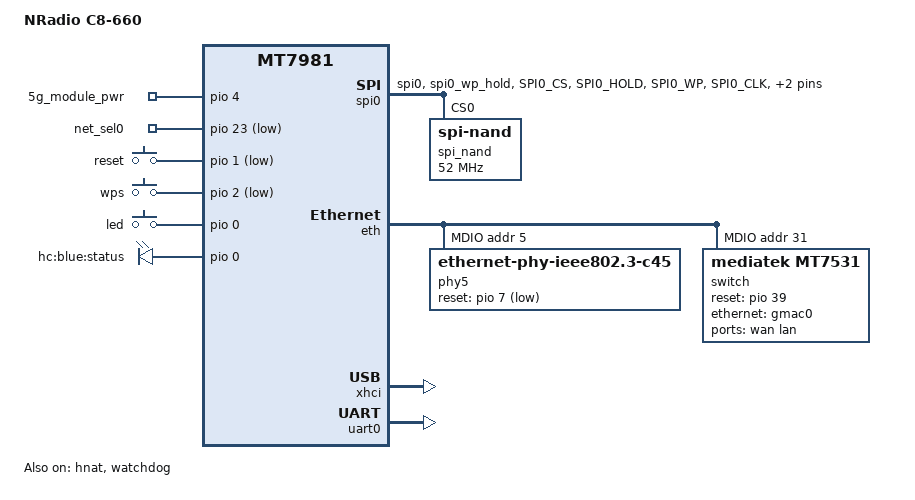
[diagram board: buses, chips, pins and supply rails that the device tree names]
//CopyRight NRadio Update By Zy143L

/dts-v1/;
#include "mt7981.dtsi"

/ {
	model = "NRadio C8-660";
	compatible = "nradio,wt9103", "mediatek,mt7981";
	
    aliases {
        led-boot = &status_blue;
        led-failsafe = &status_blue;
        led-running = &status_blue;
        led-upgrade = &status_blue;
    };

    chosen {
        bootargs = "console=ttyS0,115200n1 loglevel=8  \
                earlycon=uart8250,mmio32,0x11002000";
    };

    gpio-export {
        compatible = "gpio-export";

        cpepower {
            gpio-export,name = "5g_module_pwr";
            gpio-export,output = <1>;
            gpios = <&pio 4 GPIO_ACTIVE_HIGH>;
        };

        cpesel0 {
            gpio-export,name = "net_sel0";
            gpio-export,output = <0>;
            gpios = <&pio 23 GPIO_ACTIVE_LOW>;
        };
    };

    gpio-keys {
        compatible = "gpio-keys";

        button-reset {
            label = "reset";
            linux,code = <KEY_RESTART>;
            gpios = <&pio 1 GPIO_ACTIVE_LOW>;
        };

        button-wps {
            label = "wps";
            linux,code = <KEY_WPS_BUTTON>;
            gpios = <&pio 2 GPIO_ACTIVE_LOW>;
        };

        button-led {
            label = "led";
            linux,code = <KEY_POWER>;
            gpios = <&pio 0 GPIO_ACTIVE_HIGH>;
        };
    };

    gpio-leds {
        compatible = "gpio-leds";

        status_blue: status {
            label = "hc:blue:status";
            gpios = <&pio 0 GPIO_ACTIVE_HIGH>;
        };
    };


    nmbm_spim_nand {
        compatible = "generic,nmbm";

        #address-cells = <1>;
        #size-cells = <1>;

        lower-mtd-device = <&spi_nand>;
        forced-create;

        partitions {
            compatible = "fixed-partitions";
            #address-cells = <1>;
            #size-cells = <1>;

            partition@0 {
                label = "BL2";
                reg = <0x00000 0x0100000>;
                read-only;
            };

            partition@100000 {
                label = "u-boot-env";
                reg = <0x0100000 0x0080000>;
            };

            partition@180000 {
                label = "factory";
                reg = <0x180000 0x0180000>;
            };

            partition@300000 {
                label = "bdinfo";
                reg = <0x300000 0x0080000>;
            };

            partition@380000 {
                label = "FIP";
                reg = <0x380000 0x0200000>;
            };

            partition@580000 {
                label = "ubi";
                reg = <0x580000 0x7000000>;
            };
        };
    };
};


&spi0 {
    pinctrl-names = "default";
    pinctrl-0 = <&spi0_flash_pins>;
    status = "okay";
    spi_nand: spi_nand@0 {
        #address-cells = <1>;
        #size-cells = <1>;
        compatible = "spi-nand";
        spi-cal-enable;
        spi-cal-mode = "read-data";
        spi-cal-datalen = <7>;
        spi-cal-data = /bits/ 8 <0x53 0x50 0x49 0x4E 0x41 0x4E 0x44>;
        spi-cal-addrlen = <5>;
        spi-cal-addr = /bits/ 32 <0x0 0x0 0x0 0x0 0x0>;
        reg = <0>;
        spi-max-frequency = <52000000>;
        spi-tx-buswidth = <4>;
        spi-rx-buswidth = <4>;
    };
};

&pio {
    status = "okay";
    spi0_flash_pins: spi0-pins {
        mux {
            function = "spi";
            groups = "spi0", "spi0_wp_hold";
        };

        conf-pu {
            pins = "SPI0_CS", "SPI0_HOLD", "SPI0_WP";
            drive-strength = <MTK_DRIVE_8mA>;
            bias-pull-up = <MTK_PUPD_SET_R1R0_11>;
        };

        conf-pd {
            pins = "SPI0_CLK", "SPI0_MOSI", "SPI0_MISO";
            drive-strength = <MTK_DRIVE_8mA>;
            bias-pull-down = <MTK_PUPD_SET_R1R0_11>;
        };
    };
};

&eth {
    status = "okay";

    gmac0: mac@0 {
        compatible = "mediatek,eth-mac";
        reg = <0>;
        phy-mode = "2500base-x";

        fixed-link {
            speed = <1000>;
            full-duplex;
            pause;
        };
    };

    mdio: mdio-bus {
        #address-cells = <1>;
        #size-cells = <0>;

        phy5: phy@5 {
            compatible = "ethernet-phy-ieee802.3-c45";
            reg = <5>;
            reset-gpios = <&pio 7 1>;
            reset-assert-us = <600>;
            reset-deassert-us = <20000>;
            phy-mode = "1000base-x";
        };

        switch@0 {
            compatible = "mediatek,mt7531";
            reg = <31>;
            reset-gpios = <&pio 39 0>;

            ports {
                #address-cells = <1>;
                #size-cells = <0>;

                port@5 {
                    reg = <5>;
                    label = "wan";
                    phy-mode = "1000base-x";
                };

                port@6 {
                    reg = <6>;
                    label = "lan";
                    ethernet = <&gmac0>;
                    phy-mode = "1000base-x";

                    fixed-link {
                        speed = <1000>;
                        full-duplex;
                        pause;
                    };
                };
            };
        };
    };
};

&xhci {
    status = "okay";
};

&hnat {
    mtketh-wan = "eth1";
    mtketh-lan = "lan";
    mtketh-max-gmac = <2>;
    ext-devices-prefix = "usb", "wwan";
    status = "okay";
};

&uart0 {
    status = "okay";
};

&watchdog {
    status = "okay";
};
